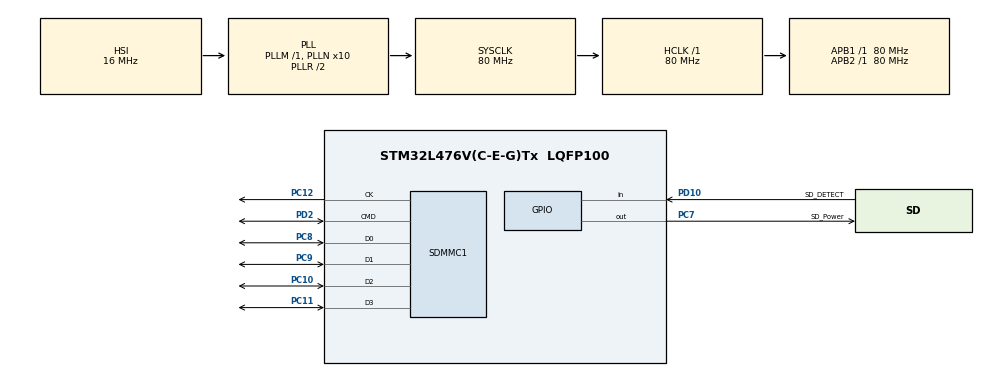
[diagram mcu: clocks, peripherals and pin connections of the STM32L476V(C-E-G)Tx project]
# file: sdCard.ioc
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Dma.Request0=SDMMC1
Dma.SDMMC1.0.Direction=DMA_PERIPH_TO_MEMORY
Dma.SDMMC1.0.Instance=DMA2_Channel4
Dma.SDMMC1.0.MemDataAlignment=DMA_MDATAALIGN_WORD
Dma.SDMMC1.0.MemInc=DMA_MINC_ENABLE
Dma.SDMMC1.0.Mode=DMA_NORMAL
Dma.SDMMC1.0.PeriphDataAlignment=DMA_PDATAALIGN_WORD
Dma.SDMMC1.0.PeriphInc=DMA_PINC_DISABLE
Dma.SDMMC1.0.Priority=DMA_PRIORITY_HIGH
FREERTOS.Tasks01=defaultTask,0,1024,StartDefaultTask,Default,NULL,Dynamic,NULL,NULL
FREERTOS.configTOTAL_HEAP_SIZE=10000
FREERTOS.configUSE_NEWLIB_REENTRANT=1
Mcu.Family=STM32L4
Mcu.Name=STM32L476V(C-E-G)Tx
Mcu.Package=LQFP100
NVIC.DMA2_Channel4_IRQn=true\:5\:0\:true\:false\:true\:false\:false\:true\:true
NVIC.PriorityGroup=NVIC_PRIORITYGROUP_4
NVIC.SDMMC1_IRQn=true\:5\:0\:false\:false\:true\:true\:true\:true\:true
NVIC.TIM6_DAC_IRQn=true\:15\:0\:false\:false\:true\:false\:false\:true\:true
NVIC.TimeBase=TIM6_DAC_IRQn
NVIC.TimeBaseIP=TIM6
PC10.Mode=SD_4_bits_Wide_bus
PC10.Signal=SDMMC1_D2
PC11.Mode=SD_4_bits_Wide_bus
PC11.Signal=SDMMC1_D3
PC12.Mode=SD_4_bits_Wide_bus
PC12.Signal=SDMMC1_CK
PC7.GPIO_Label=SD_Power
PC7.PinState=GPIO_PIN_SET
PC7.Signal=GPIO_Output
PC8.Mode=SD_4_bits_Wide_bus
PC8.Signal=SDMMC1_D0
PC9.Mode=SD_4_bits_Wide_bus
PC9.Signal=SDMMC1_D1
PD10.GPIO_Label=SD_DETECT
PD10.Signal=GPIO_Input
PD2.Mode=SD_4_bits_Wide_bus
PD2.Signal=SDMMC1_CMD
ProjectManager.HeapSize=0x200
ProjectManager.StackSize=0x400
ProjectManager.TargetToolchain=CMake
RCC.ADCFreq_Value=96000000
RCC.AHBFreq_Value=80000000
RCC.APB1Freq_Value=80000000
RCC.APB1TimFreq_Value=80000000
RCC.APB2Freq_Value=80000000
RCC.APB2TimFreq_Value=80000000
RCC.CortexFreq_Value=80000000
RCC.HCLKFreq_Value=80000000
RCC.HSE_VALUE=8000000
RCC.HSI_VALUE=16000000
RCC.LSE_VALUE=32768
RCC.MSI_VALUE=4000000
RCC.PLLN=10
RCC.PLLSAI1N=12
RCC.PLLSAI1Q=RCC_PLLQ_DIV4
RCC.PLLSourceVirtual=RCC_PLLSOURCE_HSI
RCC.SYSCLKFreq_VALUE=80000000
RCC.SYSCLKSource=RCC_SYSCLKSOURCE_PLLCLK
RCC.USBFreq_Value=48000000
RCC.VCOOutputFreq_Value=160000000
SDMMC1.ClockDiv=4
VP_FREERTOS_VS_CMSIS_V1.Mode=CMSIS_V1
VP_SYS_VS_tim6.Mode=TIM6
board=custom

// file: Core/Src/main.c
/* USER CODE BEGIN Header */
/**
  ******************************************************************************
  * @file           : main.c
  * @brief          : Main program body
  ******************************************************************************
  * @attention
  *
  * Copyright (c) 2025 STMicroelectronics.
  * All rights reserved.
  *
  * This software is licensed under terms that can be found in the LICENSE file
  * in the root directory of this software component.
  * If no LICENSE file comes with this software, it is provided AS-IS.
  *
  ******************************************************************************
  */
/* USER CODE END Header */
#include "main.h"
#include "cmsis_os.h"

/* USER CODE BEGIN Includes */
#include "fatfs.h"

/* USER CODE END Includes */

SD_HandleTypeDef hsd1;
DMA_HandleTypeDef hdma_sdmmc1;

osThreadId defaultTaskHandle;

void SystemClock_Config(void);
static void MX_GPIO_Init(void);
static void MX_DMA_Init(void);
static void MX_SDMMC1_SD_Init(void);
void StartDefaultTask(void const * argument);

int main(void)
{

  /* MCU Configuration--------------------------------------------------------*/

  /* Reset of all peripherals, Initializes the Flash interface and the Systick. */
  HAL_Init();

  /* Configure the system clock */
  SystemClock_Config();

  /* Initialize all configured peripherals */
  MX_GPIO_Init();
  MX_DMA_Init();
  MX_SDMMC1_SD_Init();
  /* USER CODE BEGIN 2 */
  FATFS_Init();

  /* USER CODE END 2 */

  /* Create the thread(s) */
  /* definition and creation of defaultTask */
  osThreadDef(defaultTask, StartDefaultTask, osPriorityNormal, 0, 1024);
  defaultTaskHandle = osThreadCreate(osThread(defaultTask), NULL);

  /* Start scheduler */
  osKernelStart();

  /* We should never get here as control is now taken by the scheduler */

  /* Infinite loop */
  while (1)
  {

  }
}

void SystemClock_Config(void)
{
  RCC_OscInitTypeDef RCC_OscInitStruct = {0};
  RCC_ClkInitTypeDef RCC_ClkInitStruct = {0};

  /** Configure the main internal regulator output voltage
  */
  if (HAL_PWREx_ControlVoltageScaling(PWR_REGULATOR_VOLTAGE_SCALE1) != HAL_OK)
  {
    Error_Handler();
  }

  /** Initializes the RCC Oscillators according to the specified parameters
  * in the RCC_OscInitTypeDef structure.
  */
  RCC_OscInitStruct.OscillatorType = RCC_OSCILLATORTYPE_HSI;
  RCC_OscInitStruct.HSIState = RCC_HSI_ON;
  RCC_OscInitStruct.HSICalibrationValue = RCC_HSICALIBRATION_DEFAULT;
  RCC_OscInitStruct.PLL.PLLState = RCC_PLL_ON;
  RCC_OscInitStruct.PLL.PLLSource = RCC_PLLSOURCE_HSI;
  RCC_OscInitStruct.PLL.PLLM = 1;
  RCC_OscInitStruct.PLL.PLLN = 10;
  RCC_OscInitStruct.PLL.PLLP = RCC_PLLP_DIV7;
  RCC_OscInitStruct.PLL.PLLQ = RCC_PLLQ_DIV2;
  RCC_OscInitStruct.PLL.PLLR = RCC_PLLR_DIV2;
  if (HAL_RCC_OscConfig(&RCC_OscInitStruct) != HAL_OK)
  {
    Error_Handler();
  }

  /** Initializes the CPU, AHB and APB buses clocks
  */
  RCC_ClkInitStruct.ClockType = RCC_CLOCKTYPE_HCLK|RCC_CLOCKTYPE_SYSCLK
                              |RCC_CLOCKTYPE_PCLK1|RCC_CLOCKTYPE_PCLK2;
  RCC_ClkInitStruct.SYSCLKSource = RCC_SYSCLKSOURCE_PLLCLK;
  RCC_ClkInitStruct.AHBCLKDivider = RCC_SYSCLK_DIV1;
  RCC_ClkInitStruct.APB1CLKDivider = RCC_HCLK_DIV1;
  RCC_ClkInitStruct.APB2CLKDivider = RCC_HCLK_DIV1;

  if (HAL_RCC_ClockConfig(&RCC_ClkInitStruct, FLASH_LATENCY_4) != HAL_OK)
  {
    Error_Handler();
  }
}

static void MX_SDMMC1_SD_Init(void)
{

  hsd1.Instance = SDMMC1;
  hsd1.Init.ClockEdge = SDMMC_CLOCK_EDGE_RISING;
  hsd1.Init.ClockBypass = SDMMC_CLOCK_BYPASS_DISABLE;
  hsd1.Init.ClockPowerSave = SDMMC_CLOCK_POWER_SAVE_DISABLE;
  hsd1.Init.BusWide = SDMMC_BUS_WIDE_4B;
  hsd1.Init.HardwareFlowControl = SDMMC_HARDWARE_FLOW_CONTROL_DISABLE;
  hsd1.Init.ClockDiv = 4;
  if (HAL_SD_Init(&hsd1) != HAL_OK)
  {
    Error_Handler();
  }
  if (HAL_SD_ConfigWideBusOperation(&hsd1, SDMMC_BUS_WIDE_4B) != HAL_OK)
  {
    Error_Handler();
  }

}

static void MX_DMA_Init(void)
{

  /* DMA controller clock enable */
  __HAL_RCC_DMA2_CLK_ENABLE();

  /* DMA interrupt init */
  /* DMA2_Channel4_IRQn interrupt configuration */
  HAL_NVIC_SetPriority(DMA2_Channel4_IRQn, 5, 0);
  HAL_NVIC_EnableIRQ(DMA2_Channel4_IRQn);

}

static void MX_GPIO_Init(void)
{
  GPIO_InitTypeDef GPIO_InitStruct = {0};

  /* GPIO Ports Clock Enable */
  __HAL_RCC_GPIOD_CLK_ENABLE();
  __HAL_RCC_GPIOC_CLK_ENABLE();

  /*Configure GPIO pin Output Level */
  HAL_GPIO_WritePin(SD_Power_GPIO_Port, SD_Power_Pin, GPIO_PIN_SET);

  /*Configure GPIO pin : SD_DETECT_Pin */
  GPIO_InitStruct.Pin = SD_DETECT_Pin;
  GPIO_InitStruct.Mode = GPIO_MODE_INPUT;
  GPIO_InitStruct.Pull = GPIO_NOPULL;
  HAL_GPIO_Init(SD_DETECT_GPIO_Port, &GPIO_InitStruct);

  /*Configure GPIO pin : SD_Power_Pin */
  GPIO_InitStruct.Pin = SD_Power_Pin;
  GPIO_InitStruct.Mode = GPIO_MODE_OUTPUT_PP;
  GPIO_InitStruct.Pull = GPIO_NOPULL;
  GPIO_InitStruct.Speed = GPIO_SPEED_FREQ_LOW;
  HAL_GPIO_Init(SD_Power_GPIO_Port, &GPIO_InitStruct);

}

void StartDefaultTask(void const * argument)
{
  for(;;)
  {
    osDelay(1);
  }
}

void HAL_TIM_PeriodElapsedCallback(TIM_HandleTypeDef *htim)
{
  if (htim->Instance == TIM6)
  {
    HAL_IncTick();
  }
}

void Error_Handler(void)
{
  __disable_irq();
  while (1)
  {
  }
}

#ifdef  USE_FULL_ASSERT
/**
  * @brief  Reports the name of the source file and the source line number
  *         where the assert_param error has occurred.
  * @param  file: pointer to the source file name
  * @param  line: assert_param error line source number
  * @retval None
  */
void assert_failed(uint8_t *file, uint32_t line)
{
  /* USER CODE BEGIN 6 */
  (void)file;
  (void)line;
  /* User can add his own implementation to report the file name and line number,
     ex: printf("Wrong parameters value: file %s on line %d\r\n", file, line) */
  /* USER CODE END 6 */
}
#endif /* USE_FULL_ASSERT */

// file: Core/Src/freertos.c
/* USER CODE BEGIN Header */
/**
  ******************************************************************************
  * File Name          : freertos.c
  * Description        : Code for freertos applications
  ******************************************************************************
  * @attention
  *
  * <h2><center>&copy; Copyright (c) 2022 STMicroelectronics.
  * All rights reserved.</center></h2>
  *
  * This software component is licensed by ST under Ultimate Liberty license
  * SLA0044, the "License"; You may not use this file except in compliance with
  * the License. You may obtain a copy of the License at:
  *                             www.st.com/SLA0044
  *
  ******************************************************************************
  */
/* USER CODE END Header */

#include "FreeRTOS.h"
#include "task.h"
#include "main.h"

/* USER CODE BEGIN Includes */
#include "fatfs.h"
#include "stdio.h"
#include "string.h"
#include "stdbool.h"
/* USER CODE END Includes */

/* GetIdleTaskMemory prototype (linked to static allocation support) */
void vApplicationGetIdleTaskMemory( StaticTask_t **ppxIdleTaskTCBBuffer, StackType_t **ppxIdleTaskStackBuffer, uint32_t *pulIdleTaskStackSize );

/* USER CODE BEGIN GET_IDLE_TASK_MEMORY */
static StaticTask_t xIdleTaskTCBBuffer;
static StackType_t xIdleStack[configMINIMAL_STACK_SIZE];

void vApplicationGetIdleTaskMemory( StaticTask_t **ppxIdleTaskTCBBuffer, StackType_t **ppxIdleTaskStackBuffer, uint32_t *pulIdleTaskStackSize )
{
  *ppxIdleTaskTCBBuffer = &xIdleTaskTCBBuffer;
  *ppxIdleTaskStackBuffer = &xIdleStack[0];
  *pulIdleTaskStackSize = configMINIMAL_STACK_SIZE;
  /* place for user code */
}
/* USER CODE END GET_IDLE_TASK_MEMORY */
